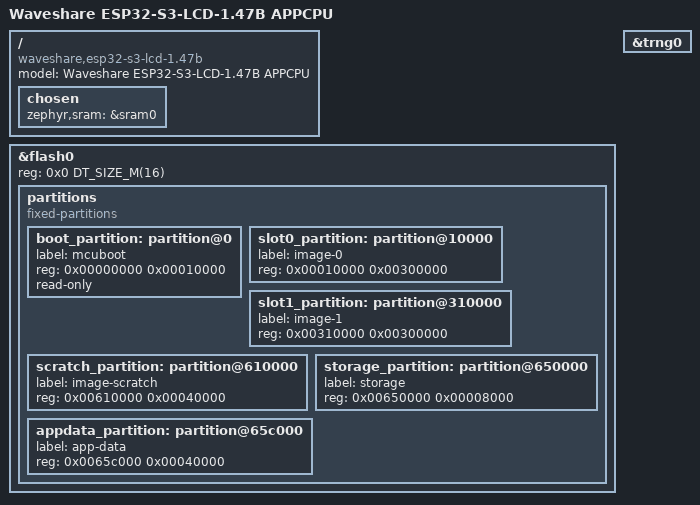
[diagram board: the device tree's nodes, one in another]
/*
 * Waveshare ESP32-S3-LCD-1.47B (rev B3) APPCPU
 */

/dts-v1/;
#include <espressif/esp32s3/esp32s3_appcpu.dtsi>

/ {
	model = "Waveshare ESP32-S3-LCD-1.47B APPCPU";
	compatible = "waveshare,esp32-s3-lcd-1.47b";

	chosen {
		zephyr,sram = &sram0;
	};
};

&flash0 {
	status = "okay";
	reg = <0x0 DT_SIZE_M(16)>;

	partitions {
		compatible = "fixed-partitions";
		#address-cells = <1>;
		#size-cells = <1>;

		boot_partition: partition@0 {
			label = "mcuboot";
			reg = <0x00000000 0x00010000>;
			read-only;
		};

		slot0_partition: partition@10000 {
			label = "image-0";
			reg = <0x00010000 0x00300000>;
		};

		slot1_partition: partition@310000 {
			label = "image-1";
			reg = <0x00310000 0x00300000>;
		};

		scratch_partition: partition@610000 {
			label = "image-scratch";
			reg = <0x00610000 0x00040000>;
		};

		storage_partition: partition@650000 {
			label = "storage";
			reg = <0x00650000 0x00008000>;
		};

		appdata_partition: partition@65c000 {
			label = "app-data";
			reg = <0x0065c000 0x00040000>;
		};
	};
};

&trng0 {
	status = "okay";
};
